# RZT2ME register map
Vendor: Renesas Electronics Corporation; Series: RZT; File version: 1.00.00
CPU: other r0p0, little endian, MPU, no FPU, VTOR, 4 interrupt priority bits, 624 interrupts
Registers are 32-bit, read-write, reset 0x0 unless marked. A register's access mark holds for its fields unless they carry their own. Offsets are from the block's base; [hi:lo] are bit positions; {n}, {i} and the like mark numbered series; 'fields as' and 'values as' point back to an identical list.

## TSU — Temperature Sensor Unit
Base 0x80046000
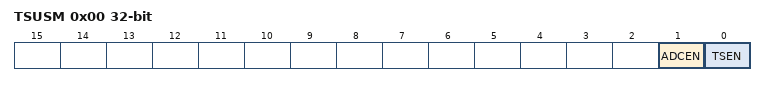
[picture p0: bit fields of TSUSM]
0x00 TSUSM — Sensor Mode Register
  [1] ADCEN — ADC Enable
    0=Disabled; 1=Enabled
  [0] TSEN — Temperature Sensor Enable
    0=Disabled; 1=Enabled
0x04 TSUST — Sensor Trigger Register
  [0] START — A/D Conversion Control
    0=Stops A/D conversion; 1=Starts A/D conversion
0x08 TSUSCS reset 0x1 — Sensor Configuration Setting Register
  [3] CKDIV — Divider Value for PCLKL
    0=24 for PCLKL = 50 MHz; 1=16 for PCLKL = 37.5 MHz
0x0C TSUSAD ro — Sensor ADC Data Register
  [11:0] DOUT — Temperature Sensor Data Output
0x10 TSUSS ro — Sensor Status Register
  [0] CONV — A/D Conversion Status
    0=Stop; 1=A/D conversion is running

## POEG1 — GPT Port Output Enable 1
Base 0x80047000
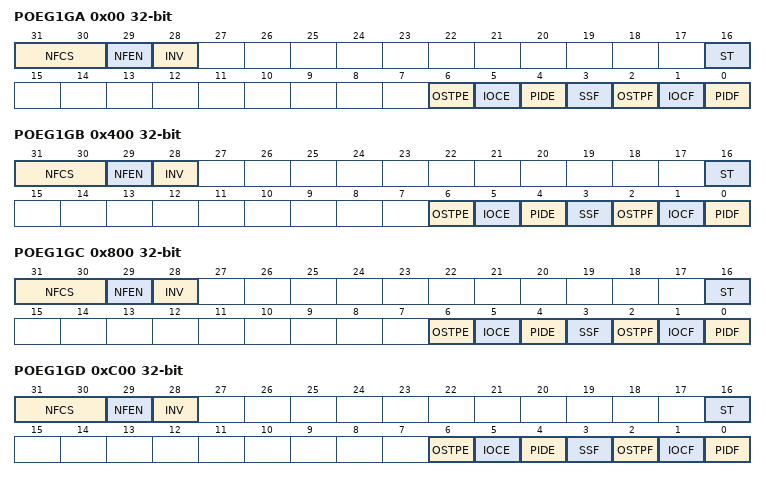
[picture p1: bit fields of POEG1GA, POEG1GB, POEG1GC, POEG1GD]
0x00 POEG1GA — POEG1 Group A Setting Register
  [31:30] NFCS — Noise filter Clock Select
    0=Samples the input level of GTETRGn pin three times per PCLKL clock; 1=Samples the input level of GTETRGn pin three times per PCLKL/8 clock; 2=Samples the input level of GTETRGn pin three times per PCLKL/32 clock; 3=Samples the input level of GTETRGn pin three times per PCLKL/128 clock
  [29] NFEN — Noise filter Enable
    0=Digital noise filter on the GTETRGn pin is disabled; 1=Digital noise filter on the GTETRGn pin is enabled
  [28] INV — GTETRGn Input Inverting
    0=Input on the GTETRGn pin is not inverted; 1=Input on the GTETRGn pin is inverted
  [16] ST ro — GTETRGn Input Status Flag
    0=GTETRGn input after filtering was 0; 1=GTETRGn input after filtering was 1
  [6] OSTPE — Enable Stopping Output on Stopping of Oscillation
    0=Detection of stopping of oscillation is disabled; 1=Detection of stopping of oscillation is enabled
  [5] IOCE — GPT Output Stop Request Enable
    0=Detection of stopping of output from the GPT is disabled; 1=Detection of stopping of output from the GPT is enabled
  [4] PIDE — Port Input Detection Enable
    0=Detection of input levels on the corresponding GTETRGn pin is disabled; 1=Detection of input levels on the corresponding GTETRGn pin is enabled
  [3] SSF — Software Stop Flag
    0=Software has not stopped output; 1=Software has stopped output
  [2] OSTPF — Oscillation Stop Detection Flag
    0=Stopping of oscillation was not detected; 1=Stopping of oscillation was detected
  [1] IOCF — GPT Output Stop Request Detection Flag
    0=Stopping of GPT output was not detected; 1=Stopping of GPT output was detected
  [0] PIDF — Port Input Detection Flag
    0=The selected input level was not detected on the GTETRGn pin; 1=The selected input level was detected on the GTETRGn pin
0x400 POEG1GB — POEG1 Group B Setting Register
  fields as POEG1GA
0x800 POEG1GC — POEG1 Group C Setting Register
  fields as POEG1GA
0xC00 POEG1GD — POEG1 Group D Setting Register
  fields as POEG1GA

## POEG2 — GPT Port Output Enable 2
Base 0x8100A000
Registers as POEG1 (with POEG1 read as POEG2).

## ICU_NS — Interrupt Controller in Non Safety Domain
Base 0x80090000
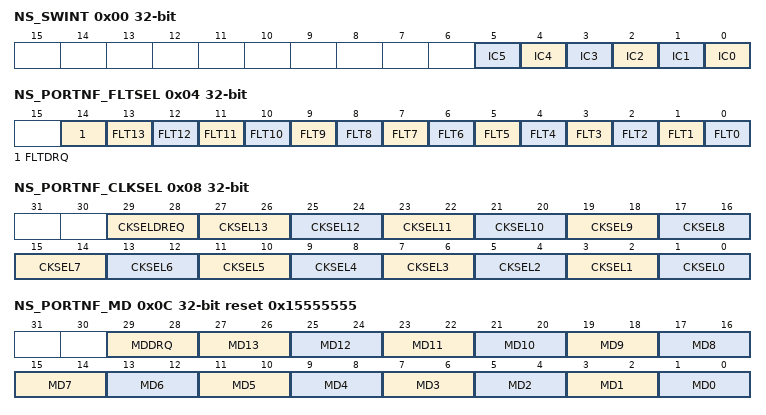
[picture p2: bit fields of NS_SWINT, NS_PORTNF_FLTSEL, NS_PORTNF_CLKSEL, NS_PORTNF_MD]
0x00 NS_SWINT wo — Software Interrupt Register
  [n] IC{n} (n=0..5) — Software Interrupt register
0x04 NS_PORTNF_FLTSEL — Interrupt Noise Filter Enable Register
  [all] fields
    0=Disable; 1=Enable
  [14] FLTDRQ — Noise filter enable for External DMA request (DREQ)
  [n] FLT{n} (n=0..13) — Noise filter enable for IRQ{n}
0x08 NS_PORTNF_CLKSEL — Interrupt Noise Filter Setting Register
  [all] fields
    0=Divided by 1; 1=Divided by 8; 2=Divided by 32; 3=Divided by 64
  [29:28] CKSELDREQ — Noise filter sampling clock selector
  [2n+1:2n] CKSEL{n} (n=0..13) — Noise filter sampling clock selector
0x0C NS_PORTNF_MD reset 0x15555555 — Interrupt Edge Detection Setting Register
  [all] fields
    0=Low level; 1=Falling edge; 2=Rising edge; 3=Falling and rising edges
  [29:28] MDDRQ — Select detection mode for DREQ of DMAC
  [2n+1:2n] MD{n} (n=0..13) — Select detection mode for IRQ{n}
